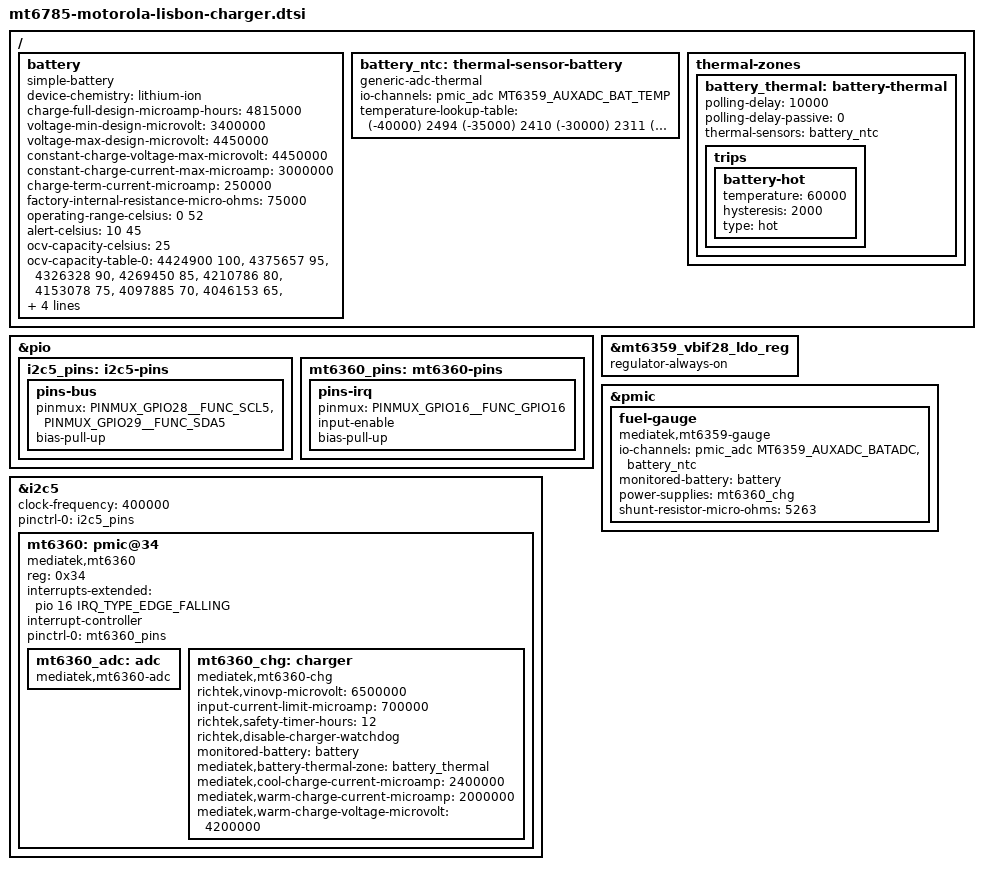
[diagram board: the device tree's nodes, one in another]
// SPDX-License-Identifier: (GPL-2.0 OR MIT)
/*
 * Motorola Moto G60s (lisbon): MT6360 charger (I2C5), battery and battery NTC.
 *
 *  - MT6360 on I2C5: PMU 0x34, PMIC 0x1a, LDO 0x64, TCPC 0x4e; IRQB on GPIO16/EINT16, falling edge.
 *  - I2C5 pins GPIO28/29 function 1 with pull-up, 400 kHz.
 *  - Charge voltage 4.45 V, termination current 250 mA (MT6360 step 50 mA).
 *  - Charge current by battery temperature: no charging below 0 degC, 2.4 A from 0 to 10 degC, 3 A
 *    from 10 to 45 degC, 2 A up to 4.2 V from 45 to 52 degC, no charging above 52 degC (enforced by
 *    the charger driver with 2 K hysteresis).
 *  - Battery SB18C77775, Qmax 4815 mAh, OCV table at 25 degC.
 *  - NTC 10 kOhm, pull-up 24 kOhm to VBIF28 (2.8 V); VBIF28 must stay on.
 * Not described: MT6360 regulators (BUCK1/2 and LDO6/7 supply the DRAM, LDO2 the touch controller),
 * MT6360 LEDs, BQ2597x charge pumps (I2C3 0x65/0x66). Type-C/PD and OTG are described in
 * mt6785-motorola-lisbon-typec.dtsi.
 */

#include <dt-bindings/iio/adc/mediatek,mt6359-auxadc.h>
#include <dt-bindings/interrupt-controller/irq.h>
#include <dt-bindings/pinctrl/mediatek,mt6785-pinfunc.h>
#include <dt-bindings/thermal/thermal.h>

/ {
	battery: battery {
		compatible = "simple-battery";
		device-chemistry = "lithium-ion";
		charge-full-design-microamp-hours = <4815000>;
		voltage-min-design-microvolt = <3400000>;
		voltage-max-design-microvolt = <4450000>;
		constant-charge-voltage-max-microvolt = <4450000>;
		/* about 0.6 C */
		constant-charge-current-max-microamp = <3000000>;
		charge-term-current-microamp = <250000>;
		/*
		 * Internal resistance of the vendor gauge profile at 25 degC (64..73 mOhm between 5
		 * and 95 %) plus 10 mOhm meter resistance
		 */
		factory-internal-resistance-micro-ohms = <75000>;
		/*
		 * Charging between 0 and 52 degC, reduced from 0 to 10 and from 45 to 52 degC
		 * (mediatek,cool/warm-*)
		 */
		operating-range-celsius = <0 52>;
		alert-celsius = <10 45>;

		ocv-capacity-celsius = <25>;
		/* From the vendor gauge profile at 25 degC, capacity relative to Qmax */
		ocv-capacity-table-0 =
			<4424900 100>, <4375657 95>, <4326328 90>, <4269450 85>,
			<4210786 80>, <4153078 75>, <4097885 70>, <4046153 65>,
			<3992415 60>, <3929581 55>, <3891053 50>, <3861110 45>,
			<3835941 40>, <3815115 35>, <3795460 30>, <3770434 25>,
			<3746588 20>, <3718438 15>, <3693683 10>, <3674056 5>,
			<3399821 0>;
	};

	battery_ntc: thermal-sensor-battery {
		compatible = "generic-adc-thermal";
		#thermal-sensor-cells = <0>;
		#io-channel-cells = <0>;
		io-channels = <&pmic_adc MT6359_AUXADC_BAT_TEMP>;
		io-channel-names = "sensor-channel";
		/* mC, mV: V = 2800 mV * R / (R + 24 kOhm), R from the NTC table */
		temperature-lookup-table = <
			(-40000) 2494  (-35000) 2410  (-30000) 2311  (-25000) 2198
			(-20000) 2071  (-15000) 1935  (-10000) 1790  (-5000) 1639
			0 1488  5000 1340  10000 1197  15000 1062
			20000 938  25000 824  30000 720  35000 629
			40000 548  45000 476  50000 414  55000 359
			60000 312  65000 273  70000 238>;
	};

	thermal-zones {
		battery_thermal: battery-thermal {
			polling-delay = <10000>;
			polling-delay-passive = <0>;
			thermal-sensors = <&battery_ntc>;

			trips {
				/* Notification only, no shutdown */
				battery-hot {
					temperature = <60000>;
					hysteresis = <2000>;
					type = "hot";
				};
			};
		};
	};
};

&pio {
	i2c5_pins: i2c5-pins {
		pins-bus {
			pinmux = <PINMUX_GPIO28__FUNC_SCL5>,
				 <PINMUX_GPIO29__FUNC_SDA5>;
			bias-pull-up;
		};
	};

	mt6360_pins: mt6360-pins {
		pins-irq {
			pinmux = <PINMUX_GPIO16__FUNC_GPIO16>;
			input-enable;
			bias-pull-up;
		};
	};
};

/* BATON bias, enabled by the bootloader, must stay on */
&mt6359_vbif28_ldo_reg {
	regulator-always-on;
};

&i2c5 {
	clock-frequency = <400000>;
	pinctrl-names = "default";
	pinctrl-0 = <&i2c5_pins>;
	status = "okay";

	mt6360: pmic@34 {
		compatible = "mediatek,mt6360";
		reg = <0x34>;
		interrupts-extended = <&pio 16 IRQ_TYPE_EDGE_FALLING>;
		interrupt-names = "IRQB";
		interrupt-controller;
		#interrupt-cells = <1>;
		pinctrl-names = "default";
		pinctrl-0 = <&mt6360_pins>;

		mt6360_adc: adc {
			compatible = "mediatek,mt6360-adc";
			#io-channel-cells = <1>;
		};

		mt6360_chg: charger {
			compatible = "mediatek,mt6360-chg";
			/* 5 V sources only: input overvoltage at 6.5 V */
			richtek,vinovp-microvolt = <6500000>;
			/*
			 * Input current limit 700 mA: at 500 mA the idle system load (about 250 mA
			 * at the USB input) leaves only about 160 mA for the battery. If the source
			 * sags, the MT6360 regulates through MIVR (4.5 V, as set by the
			 * bootloader).
			 */
			input-current-limit-microamp = <700000>;
			richtek,safety-timer-hours = <12>;
			/* Charger watchdog disabled, as in the vendor driver */
			richtek,disable-charger-watchdog;
			monitored-battery = <&battery>;
			mediatek,battery-thermal-zone = <&battery_thermal>;
			/* 0..10 degC */
			mediatek,cool-charge-current-microamp = <2400000>;
			/* 45..52 degC */
			mediatek,warm-charge-current-microamp = <2000000>;
			mediatek,warm-charge-voltage-microvolt = <4200000>;
		};
	};
};

&pmic {
	fuel-gauge {
		compatible = "mediatek,mt6359-gauge";
		io-channels = <&pmic_adc MT6359_AUXADC_BATADC>, <&battery_ntc>;
		io-channel-names = "voltage", "temperature";
		monitored-battery = <&battery>;
		power-supplies = <&mt6360_chg>;
		/*
		 * R_FG_VALUE 5 mOhm with the CAR_TUNE_VALUE gain correction of 95 % folded in: 5
		 * mOhm / 0.95
		 */
		shunt-resistor-micro-ohms = <5263>;
	};
};
